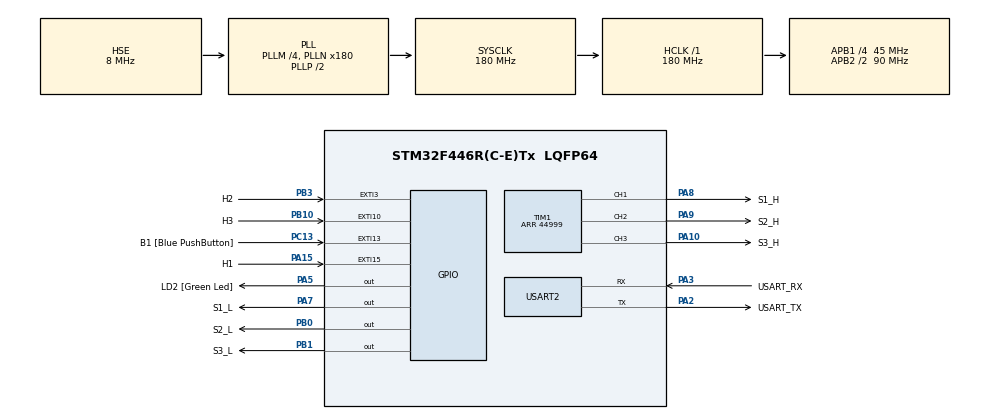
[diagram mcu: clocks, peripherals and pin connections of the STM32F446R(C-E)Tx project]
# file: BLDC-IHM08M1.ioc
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Mcu.Family=STM32F4
Mcu.Name=STM32F446R(C-E)Tx
Mcu.Package=LQFP64
NVIC.EXTI15_10_IRQn=true\:0\:0\:false\:false\:true\:true\:true
NVIC.EXTI3_IRQn=true\:0\:0\:false\:false\:true\:true\:true
NVIC.PriorityGroup=NVIC_PRIORITYGROUP_0
NVIC.TIM7_IRQn=true\:0\:0\:false\:false\:true\:true\:true
PA10.GPIO_Label=S3_H
PA10.GPIO_PuPd=GPIO_PULLDOWN
PA10.GPIO_Speed=GPIO_SPEED_FREQ_LOW
PA10.Signal=S_TIM1_CH3
PA13.GPIO_Label=TMS
PA13.Mode=Serial_Wire
PA13.Signal=SYS_JTMS-SWDIO
PA14.GPIO_Label=TCK
PA14.Mode=Serial_Wire
PA14.Signal=SYS_JTCK-SWCLK
PA15.GPIO_Label=H1
PA15.GPIO_ModeDefaultEXTI=GPIO_MODE_IT_RISING_FALLING
PA15.GPIO_PuPd=GPIO_PULLUP
PA15.Signal=GPXTI15
PA2.GPIO_Label=USART_TX
PA2.Mode=Asynchronous
PA2.Signal=USART2_TX
PA3.GPIO_Label=USART_RX
PA3.Mode=Asynchronous
PA3.Signal=USART2_RX
PA5.GPIO_Label=LD2 [Green Led]
PA5.Signal=GPIO_Output
PA7.GPIO_Label=S1_L
PA7.GPIO_PuPd=GPIO_PULLDOWN
PA7.Signal=GPIO_Output
PA8.GPIO_Label=S1_H
PA8.GPIO_PuPd=GPIO_PULLDOWN
PA8.GPIO_Speed=GPIO_SPEED_FREQ_LOW
PA8.Signal=S_TIM1_CH1
PA9.GPIO_Label=S2_H
PA9.GPIO_PuPd=GPIO_PULLDOWN
PA9.GPIO_Speed=GPIO_SPEED_FREQ_LOW
PA9.Signal=S_TIM1_CH2
PB0.GPIO_Label=S2_L
PB0.GPIO_PuPd=GPIO_PULLDOWN
PB0.Signal=GPIO_Output
PB1.GPIO_Label=S3_L
PB1.GPIO_PuPd=GPIO_PULLDOWN
PB1.Signal=GPIO_Output
PB10.GPIO_Label=H3
PB10.GPIO_ModeDefaultEXTI=GPIO_MODE_IT_RISING_FALLING
PB10.GPIO_PuPd=GPIO_PULLUP
PB10.Signal=GPXTI10
PB3.GPIO_Label=H2
PB3.GPIO_ModeDefaultEXTI=GPIO_MODE_IT_RISING_FALLING
PB3.GPIO_PuPd=GPIO_PULLUP
PB3.Signal=GPXTI3
PC13.GPIO_Label=B1 [Blue PushButton]
PC13.GPIO_ModeDefaultEXTI=GPIO_MODE_IT_FALLING
PC13.Signal=GPXTI13
PC14-OSC32_IN.Mode=LSE-External-Oscillator
PC14-OSC32_IN.Signal=RCC_OSC32_IN
PC15-OSC32_OUT.Mode=LSE-External-Oscillator
PC15-OSC32_OUT.Signal=RCC_OSC32_OUT
PH0-OSC_IN.Mode=HSE-External-Oscillator
PH0-OSC_IN.Signal=RCC_OSC_IN
PH1-OSC_OUT.Mode=HSE-External-Oscillator
PH1-OSC_OUT.Signal=RCC_OSC_OUT
ProjectManager.HeapSize=0x200
ProjectManager.StackSize=0x400
ProjectManager.TargetToolchain=STM32CubeIDE
RCC.48MHZClocksFreq_Value=84000000
RCC.AHBFreq_Value=180000000
RCC.APB1CLKDivider=RCC_HCLK_DIV4
RCC.APB1Freq_Value=45000000
RCC.APB1TimFreq_Value=90000000
RCC.APB2CLKDivider=RCC_HCLK_DIV2
RCC.APB2Freq_Value=90000000
RCC.APB2TimFreq_Value=180000000
RCC.CortexFreq_Value=180000000
RCC.FLatency-AdvancedSettings=FLASH_LATENCY_5
RCC.HCLKFreq_Value=180000000
RCC.HSE_VALUE=8000000
RCC.HSI_VALUE=16000000
RCC.PLLM=4
RCC.PLLN=180
RCC.PLLSourceVirtual=RCC_PLLSOURCE_HSE
RCC.SYSCLKFreq_VALUE=180000000
RCC.SYSCLKSource=RCC_SYSCLKSOURCE_PLLCLK
RCC.USBFreq_Value=180000000
RCC.VCOOutputFreq_Value=360000000
SH.S_TIM1_CH1.0=TIM1_CH1,PWM Generation1 CH1
SH.S_TIM1_CH2.0=TIM1_CH2,PWM Generation2 CH2
SH.S_TIM1_CH3.0=TIM1_CH3,PWM Generation3 CH3
TIM1.Channel-PWM\ Generation1\ CH1=TIM_CHANNEL_1
TIM1.Channel-PWM\ Generation2\ CH2=TIM_CHANNEL_2
TIM1.Channel-PWM\ Generation3\ CH3=TIM_CHANNEL_3
TIM1.Period=44999
TIM7.AutoReloadPreload=TIM_AUTORELOAD_PRELOAD_ENABLE
TIM7.Period=44999
TIM7.Prescaler=1
USART2.VirtualMode=VM_ASYNC
VP_TIM1_VS_ClockSourceINT.Mode=Internal
VP_TIM7_VS_ClockSourceINT.Mode=Enable_Timer
board=NUCLEO-F446RE

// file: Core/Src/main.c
/* USER CODE BEGIN Header */
/**
  ******************************************************************************
  * @file           : main.c
  * @brief          : Main program body
  ******************************************************************************
  * @attention
  *
  * <h2><center>&copy; Copyright (c) 2020 STMicroelectronics.
  * All rights reserved.</center></h2>
  *
  * This software component is licensed by ST under BSD 3-Clause license,
  * the "License"; You may not use this file except in compliance with the
  * License. You may obtain a copy of the License at:
  *                        opensource.org/licenses/BSD-3-Clause
  *
  ******************************************************************************
  */
/* USER CODE END Header */

#include "main.h"
#include "tim.h"
#include "usart.h"
#include "gpio.h"

/* USER CODE BEGIN Includes */

#include "debug.h"
#include "globals.h"
#include "six_step.h"

/* USER CODE END Includes */

void SystemClock_Config(void);

int main(void)
{

  /* MCU Configuration--------------------------------------------------------*/

  /* Reset of all peripherals, Initializes the Flash interface and the Systick. */
  HAL_Init();

  /* Configure the system clock */
  SystemClock_Config();

  /* Initialize all configured peripherals */
  MX_GPIO_Init();
  MX_USART2_UART_Init();
  MX_TIM1_Init();
  MX_TIM7_Init();
  /* USER CODE BEGIN 2 */

  // welcome message
  HAL_UART_Transmit(&huart2, (uint8_t *)WELCOME_MSG, strlen(WELCOME_MSG), HAL_MAX_DELAY);

  // Init stuff here
  glob_state = 1;
  SS_Init();

  // start timers
  HAL_TIM_Base_Start_IT(&htim7);

  // start PWM timers
  HAL_TIM_PWM_Start(&htim1, TIM_CHANNEL_1);
  HAL_TIM_PWM_Start(&htim1, TIM_CHANNEL_2);
  HAL_TIM_PWM_Start(&htim1, TIM_CHANNEL_3);

//  __HAL_TIM_SET_COMPARE(&htim1, TIM_CHANNEL_1, 10e3);
//  __HAL_TIM_SET_COMPARE(&htim1, TIM_CHANNEL_2, 10e3);
//  __HAL_TIM_SET_COMPARE(&htim1, TIM_CHANNEL_3, 10e3);

  SS_Set_Duty_Ratio(10e3);

  /* USER CODE END 2 */

  /* Infinite loop */
  while (1)
  {

  }
}

void SystemClock_Config(void)
{
  RCC_OscInitTypeDef RCC_OscInitStruct = {0};
  RCC_ClkInitTypeDef RCC_ClkInitStruct = {0};

  /** Configure the main internal regulator output voltage
  */
  __HAL_RCC_PWR_CLK_ENABLE();
  __HAL_PWR_VOLTAGESCALING_CONFIG(PWR_REGULATOR_VOLTAGE_SCALE1);
  /** Initializes the CPU, AHB and APB busses clocks
  */
  RCC_OscInitStruct.OscillatorType = RCC_OSCILLATORTYPE_HSE;
  RCC_OscInitStruct.HSEState = RCC_HSE_ON;
  RCC_OscInitStruct.PLL.PLLState = RCC_PLL_ON;
  RCC_OscInitStruct.PLL.PLLSource = RCC_PLLSOURCE_HSE;
  RCC_OscInitStruct.PLL.PLLM = 4;
  RCC_OscInitStruct.PLL.PLLN = 180;
  RCC_OscInitStruct.PLL.PLLP = RCC_PLLP_DIV2;
  RCC_OscInitStruct.PLL.PLLQ = 2;
  RCC_OscInitStruct.PLL.PLLR = 2;
  if (HAL_RCC_OscConfig(&RCC_OscInitStruct) != HAL_OK)
  {
    Error_Handler();
  }
  /** Activate the Over-Drive mode
  */
  if (HAL_PWREx_EnableOverDrive() != HAL_OK)
  {
    Error_Handler();
  }
  /** Initializes the CPU, AHB and APB busses clocks
  */
  RCC_ClkInitStruct.ClockType = RCC_CLOCKTYPE_HCLK|RCC_CLOCKTYPE_SYSCLK
                              |RCC_CLOCKTYPE_PCLK1|RCC_CLOCKTYPE_PCLK2;
  RCC_ClkInitStruct.SYSCLKSource = RCC_SYSCLKSOURCE_PLLCLK;
  RCC_ClkInitStruct.AHBCLKDivider = RCC_SYSCLK_DIV1;
  RCC_ClkInitStruct.APB1CLKDivider = RCC_HCLK_DIV4;
  RCC_ClkInitStruct.APB2CLKDivider = RCC_HCLK_DIV2;

  if (HAL_RCC_ClockConfig(&RCC_ClkInitStruct, FLASH_LATENCY_5) != HAL_OK)
  {
    Error_Handler();
  }
}

void Error_Handler(void)
{
}

/************************ (C) COPYRIGHT STMicroelectronics *****END OF FILE****/
